VERSION "HIPBNYYYYYYYYYYYYYYYYYYYYYYYYYYYNNNNNNNNNN/4/%%%/4/'%**4NNN///"

NS_ :

BS_ :

BU_ :

BO_ 2632711934 TPDT: 8 Vector__XXX
 SG_ nrSeq  : 0|8@1+ (1,0) [1|255] "" Vector__XXX
 SG_ dataPktizdByt  : 8|56@1+ (1,0) [1|1.15292150460684E+18] "" Vector__XXX

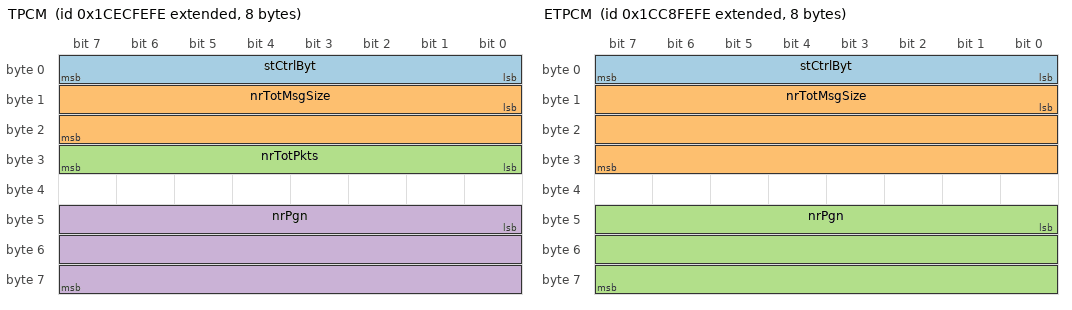
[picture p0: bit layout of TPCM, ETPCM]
BO_ 2632777470 TPCM: 8 Vector__XXX
 SG_ stCtrlByt  : 0|8@1+ (1,0) [0|255] "" Vector__XXX
 SG_ nrTotMsgSize  : 8|16@1+ (1,0) [9|1785] "" Vector__XXX
 SG_ nrTotPkts  : 24|8@1+ (1,0) [2|255] "" Vector__XXX
 SG_ nrPgn  : 40|24@1+ (1,0) [0|16777200] "" Vector__XXX

BO_ 2566839038 SOFT: 8 Vector__XXX
 SG_ nrSwIdnFields  : 0|8@1+ (1,0) [0|250] "steps" Vector__XXX
 SG_ dataSwIdn  : 8|8@1+ (1,0) [0|255] "per byte" Vector__XXX

BO_ 2565537534 RQST: 3 Vector__XXX
 SG_ nrPgn  : 0|24@1+ (1,0) [0|16777215] "" Vector__XXX

BO_ 2565868035 RngChkPrm: 32 Vector__XXX
 SG_ stErrDetnRngChkPrm0  : 0|32@1+ (1,0) [0|4294967295] "" Vector__XXX
 SG_ stErrDetnRngChkPrm1  : 32|32@1+ (1,0) [0|4294967295] "" Vector__XXX
 SG_ stErrDetnRngChkPrm2  : 64|32@1+ (1,0) [0|4294967295] "" Vector__XXX
 SG_ stErrDetnRngChkPrm3  : 96|32@1+ (1,0) [0|4294967295] "" Vector__XXX
 SG_ stErrDetnRngChkPrm4  : 128|32@1+ (1,0) [0|4294967295] "" Vector__XXX
 SG_ stErrDetnRngChkPrm5  : 160|32@1+ (1,0) [0|4294967295] "" Vector__XXX
 SG_ stErrDetnRngChkPrm6  : 192|32@1+ (1,0) [0|4294967295] "" Vector__XXX
 SG_ stErrDetnRngChkPrm7  : 224|32@1+ (1,0) [0|4294967295] "" Vector__XXX

BO_ 2565868291 RngChkInp: 32 Vector__XXX
 SG_ stErrDetnRngChkInpSig0  : 0|32@1+ (1,0) [0|4294967295] "" Vector__XXX
 SG_ stErrDetnRngChkInpSig1  : 32|32@1+ (1,0) [0|4294967295] "" Vector__XXX
 SG_ stErrDetnRngChkInpSig2  : 64|32@1+ (1,0) [0|4294967295] "" Vector__XXX
 SG_ stErrDetnRngChkInpSig3  : 96|32@1+ (1,0) [0|4294967295] "" Vector__XXX
 SG_ stErrDetnRngChkInpSig4  : 128|32@1+ (1,0) [0|4294967295] "" Vector__XXX
 SG_ stErrDetnRngChkInpSig5  : 160|32@1+ (1,0) [0|4294967295] "" Vector__XXX
 SG_ stErrDetnRngChkInpSig6  : 192|32@1+ (1,0) [0|4294967295] "" Vector__XXX
 SG_ stErrDetnRngChkInpSig7  : 224|32@1+ (1,0) [0|4294967295] "" Vector__XXX

BO_ 2559835902 NM: 8 Vector__XXX
 SG_ stChecksErrCod  : 0|8@1+ (1,0) [0|5] "" Vector__XXX
 SG_ flgMnfcCodQlfr  : 8|1@1+ (1,0) [0|1] "" Vector__XXX
 SG_ flgEcuInstQlfr  : 9|1@1+ (1,0) [0|1] "" Vector__XXX
 SG_ flgFctInstQlfr  : 10|1@1+ (1,0) [0|1] "" Vector__XXX
 SG_ flgFctQlfr  : 11|1@1+ (1,0) [0|1] "" Vector__XXX
 SG_ flgVehSysQlfr  : 12|1@1+ (1,0) [0|1] "" Vector__XXX
 SG_ flgVehSysInstQlfr  : 13|1@1+ (1,0) [0|1] "" Vector__XXX
 SG_ flgIndtryGroupQlfr  : 14|1@1+ (1,0) [0|1] "" Vector__XXX
 SG_ flgArbitraryAdrCapableQlfr  : 15|1@1+ (1,0) [0|1] "" Vector__XXX
 SG_ stNameMngtCtrlModIndcr  : 16|4@1+ (1,0) [0|15] "" Vector__XXX
 SG_ dataCmddMnfcCod  : 21|11@1+ (1,0) [0|2047] "" Vector__XXX
 SG_ dataCmddEcuInst  : 32|3@1+ (1,0) [0|7] "" Vector__XXX
 SG_ dataCmddFctInst  : 35|5@1+ (1,0) [0|31] "" Vector__XXX
 SG_ dataCmddFct  : 40|8@1+ (1,0) [0|255] "" Vector__XXX
 SG_ dataCmddVehSys  : 49|7@1+ (1,0) [0|127] "" Vector__XXX
 SG_ dataCmddVehSysInst  : 56|4@1+ (1,0) [0|15] "" Vector__XXX
 SG_ dataCmddIndtryGroup  : 60|3@1+ (1,0) [0|7] "" Vector__XXX
 SG_ flgCmddArbitraryAdrCapable  : 63|1@1+ (1,0) [0|1] "" Vector__XXX

BO_ 2630352638 ETPDT: 8 Vector__XXX
 SG_ nrSeq  : 0|8@1+ (1,0) [1|255] "" Vector__XXX
 SG_ dataPktizdByt  : 8|56@1+ (1,0) [1|1.15292150460684E+18] "" Vector__XXX

BO_ 2630418174 ETPCM: 8 Vector__XXX
 SG_ stCtrlByt  : 0|8@1+ (1,0) [0|255] "" Vector__XXX
 SG_ nrTotMsgSize  : 8|24@1+ (1,0) [1786|117440505] "" Vector__XXX
 SG_ nrPgn  : 40|24@1+ (1,0) [0|16777200] "" Vector__XXX

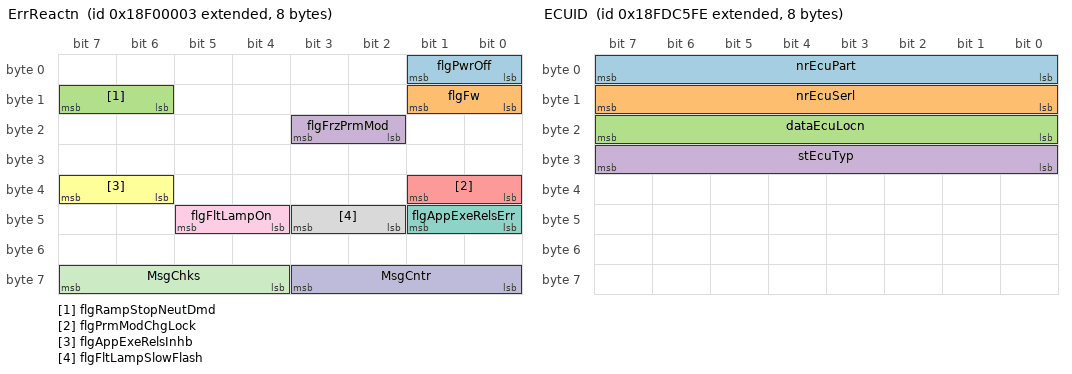
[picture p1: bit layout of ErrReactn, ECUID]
BO_ 2565865475 ErrReactn: 8 Vector__XXX
 SG_ flgPwrOff  : 0|2@1+ (1,0) [0|1] "" Vector__XXX
 SG_ flgFw  : 8|2@1+ (1,0) [0|1] "" Vector__XXX
 SG_ flgRampStopNeutDmd  : 14|2@1+ (1,0) [0|1] "" Vector__XXX
 SG_ flgFrzPrmMod  : 18|2@1+ (1,0) [0|1] "" Vector__XXX
 SG_ flgPrmModChgLock  : 32|2@1+ (1,0) [0|1] "" Vector__XXX
 SG_ flgAppExeRelsInhb  : 38|2@1+ (1,0) [0|1] "" Vector__XXX
 SG_ flgAppExeRelsErr  : 40|2@1+ (1,0) [0|1] "" Vector__XXX
 SG_ flgFltLampSlowFlash  : 42|2@1+ (1,0) [0|1] "" Vector__XXX
 SG_ flgFltLampOn  : 44|2@1+ (1,0) [0|1] "" Vector__XXX
 SG_ MsgCntr  : 56|4@1+ (1,0) [0|15] "" Vector__XXX
 SG_ MsgChks  : 60|4@1+ (1,0) [0|15] "" Vector__XXX

BO_ 2566768126 ECUID: 8 Vector__XXX
 SG_ nrEcuPart  : 0|8@1+ (1,0) [0|255] "per byte" Vector__XXX
 SG_ nrEcuSerl  : 8|8@1+ (1,0) [0|255] "per byte" Vector__XXX
 SG_ dataEcuLocn  : 16|8@1+ (1,0) [0|255] "per byte" Vector__XXX
 SG_ stEcuTyp  : 24|8@1+ (1,0) [0|255] "per byte" Vector__XXX

BO_ 2566835198 DM2: 22 Vector__XXX
 SG_ stProtLamp  : 0|2@1+ (1,0) [0|3] "" Vector__XXX
 SG_ stAmberWarnLamp  : 2|2@1+ (1,0) [0|3] "" Vector__XXX
 SG_ stRedStopLamp  : 4|2@1+ (1,0) [0|3] "" Vector__XXX
 SG_ stMalfctIndcrLamp  : 6|2@1+ (1,0) [0|3] "" Vector__XXX
 SG_ stFlashProtLamp  : 8|2@1+ (1,0) [0|3] "" Vector__XXX
 SG_ stFlashAmberWarnLamp  : 10|2@1+ (1,0) [0|3] "" Vector__XXX
 SG_ stFlashRedStopLamp  : 12|2@1+ (1,0) [0|3] "" Vector__XXX
 SG_ stFlashMalfcIndcrLamp  : 14|2@1+ (1,0) [0|3] "" Vector__XXX
 SG_ DTC1  : 16|32@1+ (1,0) [0|4294967295] "" Vector__XXX
 SG_ DTC2  : 48|32@1+ (1,0) [0|4294967295] "" Vector__XXX
 SG_ DTC3  : 80|32@1+ (1,0) [0|4294967295] "" Vector__XXX
 SG_ DTC4  : 112|32@1+ (1,0) [0|4294967295] "" Vector__XXX
 SG_ DTC5  : 144|32@1+ (1,0) [0|4294967295] "" Vector__XXX

BO_ 2564816638 DM13: 8 Vector__XXX
 SG_ stStopStrtCurDataLnk  : 6|2@1+ (1,0) [0|3] "" Vector__XXX
 SG_ stHldSig  : 28|4@1+ (1,0) [0|15] "" Vector__XXX

BO_ 2566834942 DM1: 22 Vector__XXX
 SG_ stProtLamp  : 0|2@1+ (1,0) [0|3] "" Vector__XXX
 SG_ stAmberWarnLamp  : 2|2@1+ (1,0) [0|3] "" Vector__XXX
 SG_ stRedStopLamp  : 4|2@1+ (1,0) [0|3] "" Vector__XXX
 SG_ stMalfctIndcrLamp  : 6|2@1+ (1,0) [0|3] "" Vector__XXX
 SG_ stFlashProtLamp  : 8|2@1+ (1,0) [0|3] "" Vector__XXX
 SG_ stFlashAmberWarnLamp  : 10|2@1+ (1,0) [0|3] "" Vector__XXX
 SG_ stFlashRedStopLamp  : 12|2@1+ (1,0) [0|3] "" Vector__XXX
 SG_ stFlashMalfcIndcrLamp  : 14|2@1+ (1,0) [0|3] "" Vector__XXX
 SG_ DTC1  : 16|32@1+ (1,0) [0|4294967295] "" Vector__XXX
 SG_ DTC2  : 48|32@1+ (1,0) [0|4294967295] "" Vector__XXX
 SG_ DTC3  : 80|32@1+ (1,0) [0|4294967295] "" Vector__XXX
 SG_ DTC4  : 112|32@1+ (1,0) [0|4294967295] "" Vector__XXX
 SG_ DTC5  : 144|32@1+ (1,0) [0|4294967295] "" Vector__XXX

BO_ 2566838526 CA: 9 Vector__XXX
 SG_ nrIdentity  : 0|21@1+ (1,0) [0|2097151] "" Vector__XXX
 SG_ dataMnfcCode  : 21|11@1+ (1,0) [0|2047] "" Vector__XXX
 SG_ dataEcuInst  : 32|3@1+ (1,0) [0|7] "" Vector__XXX
 SG_ dataFctInst  : 35|5@1+ (1,0) [0|31] "" Vector__XXX
 SG_ dataFct  : 40|8@1+ (1,0) [0|255] "" Vector__XXX
 SG_ dataVehSys  : 49|7@1+ (1,0) [0|127] "" Vector__XXX
 SG_ dataVehSysInst  : 56|4@1+ (1,0) [0|15] "" Vector__XXX
 SG_ dataIndtryGroup  : 60|3@1+ (1,0) [0|7] "" Vector__XXX
 SG_ flgArbitraryAdrCapable  : 63|1@1+ (1,0) [0|1] "" Vector__XXX
 SG_ adrSrcNew  : 64|8@1+ (1,0) [0|253] "" Vector__XXX

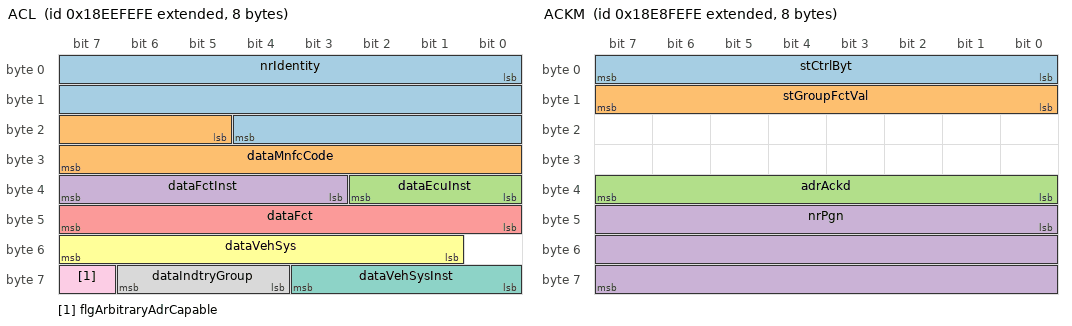
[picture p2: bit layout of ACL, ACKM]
BO_ 2565799678 ACL: 8 Vector__XXX
 SG_ nrIdentity  : 0|21@1+ (1,0) [0|2097151] "" Vector__XXX
 SG_ dataMnfcCode  : 21|11@1+ (1,0) [0|2047] "" Vector__XXX
 SG_ dataEcuInst  : 32|3@1+ (1,0) [0|7] "" Vector__XXX
 SG_ dataFctInst  : 35|5@1+ (1,0) [0|31] "" Vector__XXX
 SG_ dataFct  : 40|8@1+ (1,0) [0|255] "" Vector__XXX
 SG_ dataVehSys  : 49|7@1+ (1,0) [0|127] "" Vector__XXX
 SG_ dataVehSysInst  : 56|4@1+ (1,0) [0|15] "" Vector__XXX
 SG_ dataIndtryGroup  : 60|3@1+ (1,0) [0|7] "" Vector__XXX
 SG_ flgArbitraryAdrCapable  : 63|1@1+ (1,0) [0|1] "" Vector__XXX

BO_ 2565406462 ACKM: 8 Vector__XXX
 SG_ stCtrlByt  : 0|8@1+ (1,0) [0|3] "" Vector__XXX
 SG_ stGroupFctVal  : 8|8@1+ (1,0) [0|250] "" Vector__XXX
 SG_ adrAckd  : 32|8@1+ (1,0) [0|255] "" Vector__XXX
 SG_ nrPgn  : 40|24@1+ (1,0) [0|16777200] "" Vector__XXX

CM_ SG_ 2632711934 dataPktizdByt "Packetized Data (7 bytes).";

CM_ SG_ 2632777470 stCtrlByt "Control Byte specifiying kind of connection management message. See SAE J1939-21.";
CM_ SG_ 2632777470 nrTotMsgSize "Number of bytes to be transmitted. See SAE J1939-21.";
CM_ SG_ 2632777470 nrTotPkts "Total Number of Packets. See SAE J1939-21.";
CM_ SG_ 2632777470 nrPgn "Parameter Group Number of the packeted message. See SAE J1939-21.";

CM_ SG_ 2566839038 nrSwIdnFields "Number of software identification designators represented in the software identification parameter group";
CM_ SG_ 2566839038 dataSwIdn "Software identification of an electronic module. As an example, this parameter may be represented with ASCII characters MMDDYYaa where MM is the month, DD is the day, YY is the year, and aa is the revision number.";

CM_ SG_ 2565537534 nrPgn "Parameter Group Number of the packeted message. See SAE J1939-21.";

CM_ SG_ 2565868035 stErrDetnRngChkPrm0 "Parameter range check bits of all used functions components (Array 0)";
CM_ SG_ 2565868035 stErrDetnRngChkPrm1 "Parameter range check bits of all used functions components (Array 1)";
CM_ SG_ 2565868035 stErrDetnRngChkPrm2 "Parameter range check bits of all used functions components (Array 2)";
CM_ SG_ 2565868035 stErrDetnRngChkPrm3 "Parameter range check bits of all used functions components (Array 3)";
CM_ SG_ 2565868035 stErrDetnRngChkPrm4 "Parameter range check bits of all used functions components (Array 4)";
CM_ SG_ 2565868035 stErrDetnRngChkPrm5 "Parameter range check bits of all used functions components (Array 5)";
CM_ SG_ 2565868035 stErrDetnRngChkPrm6 "Parameter range check bits of all used functions components (Array 6)";
CM_ SG_ 2565868035 stErrDetnRngChkPrm7 "Parameter range check bits of all used functions components (Array 7)";

CM_ SG_ 2565868291 stErrDetnRngChkInpSig0 "Input range check bits of all used functions components (Array 0)";
CM_ SG_ 2565868291 stErrDetnRngChkInpSig1 "Input range check bits of all used functions components (Array 1)";
CM_ SG_ 2565868291 stErrDetnRngChkInpSig2 "Input range check bits of all used functions components (Array 2)";
CM_ SG_ 2565868291 stErrDetnRngChkInpSig3 "Input range check bits of all used functions components (Array 3)";
CM_ SG_ 2565868291 stErrDetnRngChkInpSig4 "Input range check bits of all used functions components (Array 4)";
CM_ SG_ 2565868291 stErrDetnRngChkInpSig5 "Input range check bits of all used functions components (Array 5)";
CM_ SG_ 2565868291 stErrDetnRngChkInpSig6 "Input range check bits of all used functions components (Array 6)";
CM_ SG_ 2565868291 stErrDetnRngChkInpSig7 "Input range check bits of all used functions components (Array 7)";

CM_ SG_ 2559835902 stChecksErrCod "NAME Checksum or error code depending on mode, see SAE J1939-81 chapter 4.6.2.2.1.";
CM_ SG_ 2559835902 flgMnfcCodQlfr "Manufacturer Code qualifier flag, see SAE J1939-81 chapter 4.6.2.2.2.";
CM_ SG_ 2559835902 flgEcuInstQlfr "ECU Instance qualifier flag, see SAE J1939-81 chapter 4.6.2.2.3.";
CM_ SG_ 2559835902 flgFctInstQlfr "Function Instance qualifier flag, see SAE J1939-81 chapter 4.6.2.2.4.";
CM_ SG_ 2559835902 flgFctQlfr "Function qualifier flag, see SAE J1939-81 chapter 4.6.2.2.5.";
CM_ SG_ 2559835902 flgVehSysQlfr "Vehicle system qualifier flag, see SAE J1939-81 chapter 4.6.2.2.6.";
CM_ SG_ 2559835902 flgVehSysInstQlfr "Vehicle system Instance qualifier flag, see SAE J1939-81 chapter 4.6.2.2.7.";
CM_ SG_ 2559835902 flgIndtryGroupQlfr "Industry group qualifier flag, see SAE J1939-81 chapter 4.6.2.2.8.";
CM_ SG_ 2559835902 flgArbitraryAdrCapableQlfr "Arbitrary Address Capable qualifier flag, see SAE J1939-81 chapter 4.6.2.2.9.";
CM_ SG_ 2559835902 stNameMngtCtrlModIndcr "This four bit parameter is used to define the purpose of the NM message. See SAE J1939-81 chapter 4.6.2.2.10.";
CM_ SG_ 2559835902 dataCmddMnfcCod "See SAE J1939-81 chapter 4.6.2.2.11.";
CM_ SG_ 2559835902 dataCmddEcuInst "See SAE J1939-81 chapter 4.6.2.2.12.";
CM_ SG_ 2559835902 dataCmddFctInst "See SAE J1939-81 chapter 4.6.2.2.13.";
CM_ SG_ 2559835902 dataCmddFct "See SAE J1939-81 chapter 4.6.2.2.14.";
CM_ SG_ 2559835902 dataCmddVehSys "See SAE J1939-81 chapter 4.6.2.2.15.";
CM_ SG_ 2559835902 dataCmddVehSysInst "See SAE J1939-81 chapter 4.6.2.2.16.";
CM_ SG_ 2559835902 dataCmddIndtryGroup "See SAE J1939-81 chapter 4.6.2.2.17.";
CM_ SG_ 2559835902 flgCmddArbitraryAdrCapable "See SAE J1939-81 chapter 4.6.2.2.18.";

CM_ SG_ 2630352638 dataPktizdByt "Packetized Data (7 bytes).";

CM_ SG_ 2630418174 stCtrlByt "Control Byte specifiying kind of connection management message. See SAE J1939-21.";
CM_ SG_ 2630418174 nrTotMsgSize "Number of bytes to be transmitted. See SAE J1939-21.";
CM_ SG_ 2630418174 nrPgn "Parameter Group Number of the packeted message. See SAE J1939-21.";

CM_ SG_ 2565865475 flgPwrOff "Error reaction - Emergency power off";
CM_ SG_ 2565865475 flgFw "Error reaction - Free wheeling";
CM_ SG_ 2565865475 flgRampStopNeutDmd "Error reaction - Ramp stop via neutral drive demand";
CM_ SG_ 2565865475 flgFrzPrmMod "Error reaction - Freeze drive mode";
CM_ SG_ 2565865475 flgPrmModChgLock "Error reaction - Drive mode change lock";
CM_ SG_ 2565865475 flgAppExeRelsInhb "Error reaction - Start lock that prevents vehicle movement during power on";
CM_ SG_ 2565865475 flgAppExeRelsErr "Error reaction - Inhibit first appl power on condition";
CM_ SG_ 2565865475 flgFltLampSlowFlash "Error reaction - No reaction executed, Fault Lamp slow flashing";
CM_ SG_ 2565865475 flgFltLampOn "Error reaction - No reaction executed, Fault Lamp on";
CM_ SG_ 2565865475 MsgCntr "The message counter is used to detect situations where the transmitting ECU repeats the same frame all the time. The receiver may use the counter parameter to detect this situation. The transmitting device will increase the message counter in every cycle.";
CM_ SG_ 2565865475 MsgChks "The message checksum is used to verify the signal path from the transmitting device to the receiving device.";

CM_ SG_ 2566768126 nrEcuPart "The part number of the physical ECU.";
CM_ SG_ 2566768126 nrEcuSerl "The serial number of the physical ECU.";
CM_ SG_ 2566768126 dataEcuLocn "The location of the ECU within a network.";
CM_ SG_ 2566768126 stEcuTyp "The type of ECU. One example of a use of the ECU type could be for classifying ECU capabilities, such as I/O.";

CM_ SG_ 2566835198 stProtLamp "This lamp is used to relay trouble code information that is reporting a problem with a vehicle system that is most probably not electronic subsystem related";
CM_ SG_ 2566835198 stAmberWarnLamp "This lamp is used to relay trouble code information that is reporting a problem with the vehicle system but the vehicle need not be immediately stopped";
CM_ SG_ 2566835198 stRedStopLamp "This lamp is used to relay trouble code information that is of a severe enought condition that it warrants stopping the vehicle";
CM_ SG_ 2566835198 stMalfctIndcrLamp "A lamp used to relay only emissions-related trouble code information";
CM_ SG_ 2566835198 stFlashProtLamp "This parameter provides the capability to flash the engine protect lamp (SPN 3041)";
CM_ SG_ 2566835198 stFlashAmberWarnLamp "This parameter provides the capability to flash the AWL (SPN 3040)";
CM_ SG_ 2566835198 stFlashRedStopLamp "This parameter provides the capability to flash the RSL (SPN 3039)";
CM_ SG_ 2566835198 stFlashMalfcIndcrLamp "This parameter provides the capability to flash the MIL (SPN 3038)";
CM_ SG_ 2566835198 DTC1 "Diagnostic Trouble Code";
CM_ SG_ 2566835198 DTC2 "Diagnostic Trouble Code";
CM_ SG_ 2566835198 DTC3 "Diagnostic Trouble Code";
CM_ SG_ 2566835198 DTC4 "Diagnostic Trouble Code";
CM_ SG_ 2566835198 DTC5 "Diagnostic Trouble Code";

CM_ SG_ 2564816638 stStopStrtCurDataLnk "Identifies the action to be performed on the communications port that this parameter was received on:01b = Stop Broadcast,10b = Start Broadcast";
CM_ SG_ 2564816638 stHldSig "Indicator to all nodes that the communication ports that have been acted upon by the “Stop Start Broadcast” PGN are remaining in the modified state.0000b = All Devices,0001b = Devices whose broadcast state has been modified";

CM_ SG_ 2566834942 stProtLamp "This lamp is used to relay trouble code information that is reporting a problem with a vehicle system that is most probably not electronic subsystem related";
CM_ SG_ 2566834942 stAmberWarnLamp "This lamp is used to relay trouble code information that is reporting a problem with the vehicle system but the vehicle need not be immediately stopped";
CM_ SG_ 2566834942 stRedStopLamp "This lamp is used to relay trouble code information that is of a severe enought condition that it warrants stopping the vehicle";
CM_ SG_ 2566834942 stMalfctIndcrLamp "A lamp used to relay only emissions-related trouble code information";
CM_ SG_ 2566834942 stFlashProtLamp "This parameter provides the capability to flash the engine protect lamp (SPN 3041)";
CM_ SG_ 2566834942 stFlashAmberWarnLamp "This parameter provides the capability to flash the AWL (SPN 3040)";
CM_ SG_ 2566834942 stFlashRedStopLamp "This parameter provides the capability to flash the RSL (SPN 3039)";
CM_ SG_ 2566834942 stFlashMalfcIndcrLamp "This parameter provides the capability to flash the MIL (SPN 3038)";
CM_ SG_ 2566834942 DTC1 "Diagnostic Trouble Code";
CM_ SG_ 2566834942 DTC2 "Diagnostic Trouble Code";
CM_ SG_ 2566834942 DTC3 "Diagnostic Trouble Code";
CM_ SG_ 2566834942 DTC4 "Diagnostic Trouble Code";
CM_ SG_ 2566834942 DTC5 "Diagnostic Trouble Code";

CM_ SG_ 2566838526 nrIdentity "Part of the NAME of Commanded Address Target";
CM_ SG_ 2566838526 dataMnfcCode "Part of the NAME of Commanded Address Target";
CM_ SG_ 2566838526 dataEcuInst "Part of the NAME of Commanded Address Target";
CM_ SG_ 2566838526 dataFctInst "Part of the NAME of Commanded Address Target";
CM_ SG_ 2566838526 dataFct "Part of the NAME of Commanded Address Target";
CM_ SG_ 2566838526 dataVehSys "Part of the NAME of Commanded Address Target";
CM_ SG_ 2566838526 dataVehSysInst "Part of the NAME of Commanded Address Target";
CM_ SG_ 2566838526 dataIndtryGroup "Part of the NAME of Commanded Address Target";
CM_ SG_ 2566838526 flgArbitraryAdrCapable "Part of the NAME of Commanded Address Target";
CM_ SG_ 2566838526 adrSrcNew "It contains the source address that is to be assigned to the CA matching the NAME conveyed in the first eight bytes of this Commanded Address message.";

CM_ SG_ 2565799678 nrIdentity "Part of the 8-byte Value which uniquely identifies the particular CA that is claiming the associated address.";
CM_ SG_ 2565799678 dataMnfcCode "Part of the 8-byte Value which uniquely identifies the particular CA that is claiming the associated address.";
CM_ SG_ 2565799678 dataEcuInst "Part of the 8-byte Value which uniquely identifies the particular CA that is claiming the associated address.";
CM_ SG_ 2565799678 dataFctInst "Part of the 8-byte Value which uniquely identifies the particular CA that is claiming the associated address.";
CM_ SG_ 2565799678 dataFct "Part of the 8-byte Value which uniquely identifies the particular CA that is claiming the associated address.";
CM_ SG_ 2565799678 dataVehSys "Part of the 8-byte Value which uniquely identifies the particular CA that is claiming the associated address.";
CM_ SG_ 2565799678 dataVehSysInst "Part of the 8-byte Value which uniquely identifies the particular CA that is claiming the associated address.";
CM_ SG_ 2565799678 dataIndtryGroup "Part of the 8-byte Value which uniquely identifies the particular CA that is claiming the associated address.";
CM_ SG_ 2565799678 flgArbitraryAdrCapable "Part of the 8-byte Value which uniquely identifies the particular CA that is claiming the associated address.";

CM_ SG_ 2565406462 stCtrlByt "Control byte = 0, Positive Acknowledgment (ACK);Control byte = 1, Negative Acknowledgment (NACK);Control byte = 2, Access Denied;Control byte = 3, Cannot Respond;See SAE J1939-21 chapter 5.4.4";
CM_ SG_ 2565406462 stGroupFctVal "Group Function Value, see SAE J1939-21 chapter 5.4.4.";
CM_ SG_ 2565406462 adrAckd "Address of acknowledgment depending on Control Byte.";
CM_ SG_ 2565406462 nrPgn "Parameter Group Number of the acknowledged message (depending on ControlByte). See SAE J1939-21.";

BA_DEF_ SG_  "SigType" ENUM  "Default","Range","RangeSigned","ASCII","Discrete","Control","ReferencePGN","DTC","StringDelimiter","StringLength","StringLengthControl";
BA_DEF_ SG_  "SPN" INT 0 524287;
BA_DEF_ BO_  "GenMsgRequestable" INT 0 1;
BA_DEF_ BO_  "GenMsgSendType" ENUM  "cyclic","NotUsed","NotUsed","NotUsed","NotUsed","NotUsed","NotUsed","IfActive","noMsgSendType";
BA_DEF_ BO_  "VFrameFormat" ENUM  "StandardCAN","ExtendedCAN","reserved","J1939PG";
BA_DEF_ BO_  "GenMsgCycleTime" INT 0 3600000;
BA_DEF_ BO_  "MsgCntrChksSuprtd" INT 0 3;
BA_DEF_ BU_  "NmStationAddress" INT 0 255;
BA_DEF_  "BusType" STRING ;
BA_DEF_  "ProtocolType" STRING ;
BA_DEF_DEF_  "SigType" "Default";
BA_DEF_DEF_  "SPN" 0;
BA_DEF_DEF_  "GenMsgRequestable" 1;
BA_DEF_DEF_  "GenMsgSendType" "noMsgSendType";
BA_DEF_DEF_  "VFrameFormat" "StandardCAN";
BA_DEF_DEF_  "GenMsgCycleTime" 0;
BA_DEF_DEF_  "MsgCntrChksSuprtd" 0;
BA_DEF_DEF_  "NmStationAddress" 254;
BA_DEF_DEF_  "BusType" "";
BA_DEF_DEF_  "ProtocolType" "";
BA_ "ProtocolType" "J1939";
BA_  "BusType" "CAN";

BA_ "GenMsgSendType" BO_ 2632711934 7;
BA_ "VFrameFormat" BO_ 2632711934 3;
BA_ "GenMsgSendType" BO_ 2632777470 7;
BA_ "VFrameFormat" BO_ 2632777470 3;
BA_ "VFrameFormat" BO_ 2566839038 3;
BA_ "GenMsgSendType" BO_ 2565537534 7;
BA_ "VFrameFormat" BO_ 2565537534 3;
BA_ "VFrameFormat" BO_ 2565868035 3;
BA_ "VFrameFormat" BO_ 2565868291 3;
BA_ "GenMsgSendType" BO_ 2559835902 7;
BA_ "VFrameFormat" BO_ 2559835902 3;
BA_ "GenMsgSendType" BO_ 2630352638 7;
BA_ "VFrameFormat" BO_ 2630352638 3;
BA_ "GenMsgSendType" BO_ 2630418174 7;
BA_ "VFrameFormat" BO_ 2630418174 3;
BA_ "GenMsgSendType" BO_ 2565865475 7;
BA_ "VFrameFormat" BO_ 2565865475 3;
BA_ "VFrameFormat" BO_ 2566768126 3;
BA_ "GenMsgSendType" BO_ 2566835198 7;
BA_ "VFrameFormat" BO_ 2566835198 3;
BA_ "GenMsgSendType" BO_ 2564816638 7;
BA_ "VFrameFormat" BO_ 2564816638 3;
BA_ "GenMsgSendType" BO_ 2566834942 7;
BA_ "VFrameFormat" BO_ 2566834942 3;
BA_ "GenMsgSendType" BO_ 2566838526 7;
BA_ "VFrameFormat" BO_ 2566838526 3;
BA_ "GenMsgSendType" BO_ 2565799678 7;
BA_ "VFrameFormat" BO_ 2565799678 3;
BA_ "VFrameFormat" BO_ 2565406462 3;

BA_ "SPN"  SG_ 2632711934 nrSeq 2572;
BA_ "SPN"  SG_ 2632711934 dataPktizdByt 2573;
BA_ "SPN"  SG_ 2632777470 stCtrlByt 2556;
BA_ "SigType"  SG_ 2632777470 stCtrlByt 5;
BA_ "SPN"  SG_ 2632777470 nrTotMsgSize 2557;
BA_ "SPN"  SG_ 2632777470 nrTotPkts 2558;
BA_ "SPN"  SG_ 2632777470 nrPgn 2560;
BA_ "SigType"  SG_ 2632777470 nrPgn 6;
BA_ "SPN"  SG_ 2566839038 nrSwIdnFields 965;
BA_ "SigType"  SG_ 2566839038 nrSwIdnFields 1;
BA_ "SPN"  SG_ 2566839038 dataSwIdn 234;
BA_ "SigType"  SG_ 2566839038 dataSwIdn 8;
BA_ "SPN"  SG_ 2565537534 nrPgn 2560;
BA_ "SigType"  SG_ 2565537534 nrPgn 6;
BA_ "SPN"  SG_ 2559835902 stChecksErrCod 5657;
BA_ "SigType"  SG_ 2559835902 stChecksErrCod 1;
BA_ "SPN"  SG_ 2559835902 flgMnfcCodQlfr 5658;
BA_ "SPN"  SG_ 2559835902 flgEcuInstQlfr 5659;
BA_ "SPN"  SG_ 2559835902 flgFctInstQlfr 5660;
BA_ "SPN"  SG_ 2559835902 flgFctQlfr 5661;
BA_ "SPN"  SG_ 2559835902 flgVehSysQlfr 5662;
BA_ "SPN"  SG_ 2559835902 flgVehSysInstQlfr 5663;
BA_ "SPN"  SG_ 2559835902 flgIndtryGroupQlfr 5664;
BA_ "SPN"  SG_ 2559835902 flgArbitraryAdrCapableQlfr 5665;
BA_ "SPN"  SG_ 2559835902 stNameMngtCtrlModIndcr 5666;
BA_ "SPN"  SG_ 2559835902 dataCmddMnfcCod 5667;
BA_ "SPN"  SG_ 2559835902 dataCmddEcuInst 5668;
BA_ "SPN"  SG_ 2559835902 dataCmddFctInst 5669;
BA_ "SPN"  SG_ 2559835902 dataCmddFct 5670;
BA_ "SPN"  SG_ 2559835902 dataCmddVehSys 5671;
BA_ "SPN"  SG_ 2559835902 dataCmddVehSysInst 5672;
BA_ "SPN"  SG_ 2559835902 dataCmddIndtryGroup 5673;
BA_ "SPN"  SG_ 2559835902 flgCmddArbitraryAdrCapable 5674;
BA_ "SPN"  SG_ 2630352638 nrSeq 2572;
BA_ "SPN"  SG_ 2630352638 dataPktizdByt 2573;
BA_ "SPN"  SG_ 2630418174 stCtrlByt 2556;
BA_ "SigType"  SG_ 2630418174 stCtrlByt 5;
BA_ "SPN"  SG_ 2630418174 nrTotMsgSize 2557;
BA_ "SPN"  SG_ 2630418174 nrPgn 2560;
BA_ "SigType"  SG_ 2630418174 nrPgn 6;
BA_ "SPN"  SG_ 2565865475 MsgCntr 4206;
BA_ "SPN"  SG_ 2565865475 MsgChks 4207;
BA_ "SPN"  SG_ 2566768126 nrEcuPart 2901;
BA_ "SigType"  SG_ 2566768126 nrEcuPart 8;
BA_ "SPN"  SG_ 2566768126 nrEcuSerl 2902;
BA_ "SigType"  SG_ 2566768126 nrEcuSerl 8;
BA_ "SPN"  SG_ 2566768126 dataEcuLocn 2903;
BA_ "SigType"  SG_ 2566768126 dataEcuLocn 8;
BA_ "SPN"  SG_ 2566768126 stEcuTyp 2904;
BA_ "SigType"  SG_ 2566768126 stEcuTyp 8;
BA_ "SPN"  SG_ 2566835198 stProtLamp 987;
BA_ "SigType"  SG_ 2566835198 stProtLamp 4;
BA_ "SPN"  SG_ 2566835198 stAmberWarnLamp 624;
BA_ "SigType"  SG_ 2566835198 stAmberWarnLamp 4;
BA_ "SPN"  SG_ 2566835198 stRedStopLamp 623;
BA_ "SigType"  SG_ 2566835198 stRedStopLamp 4;
BA_ "SPN"  SG_ 2566835198 stMalfctIndcrLamp 1213;
BA_ "SigType"  SG_ 2566835198 stMalfctIndcrLamp 4;
BA_ "SPN"  SG_ 2566835198 stFlashProtLamp 3041;
BA_ "SigType"  SG_ 2566835198 stFlashProtLamp 4;
BA_ "SPN"  SG_ 2566835198 stFlashAmberWarnLamp 3040;
BA_ "SigType"  SG_ 2566835198 stFlashAmberWarnLamp 4;
BA_ "SPN"  SG_ 2566835198 stFlashRedStopLamp 3039;
BA_ "SigType"  SG_ 2566835198 stFlashRedStopLamp 4;
BA_ "SPN"  SG_ 2566835198 stFlashMalfcIndcrLamp 3038;
BA_ "SigType"  SG_ 2566835198 stFlashMalfcIndcrLamp 4;
BA_ "SigType"  SG_ 2566835198 DTC1 7;
BA_ "SigType"  SG_ 2566835198 DTC2 7;
BA_ "SigType"  SG_ 2566835198 DTC3 7;
BA_ "SigType"  SG_ 2566835198 DTC4 7;
BA_ "SigType"  SG_ 2566835198 DTC5 7;
BA_ "SPN"  SG_ 2564816638 stStopStrtCurDataLnk 1230;
BA_ "SigType"  SG_ 2564816638 stStopStrtCurDataLnk 5;
BA_ "SPN"  SG_ 2564816638 stHldSig 1236;
BA_ "SigType"  SG_ 2564816638 stHldSig 5;
BA_ "SPN"  SG_ 2566834942 stProtLamp 987;
BA_ "SigType"  SG_ 2566834942 stProtLamp 4;
BA_ "SPN"  SG_ 2566834942 stAmberWarnLamp 624;
BA_ "SigType"  SG_ 2566834942 stAmberWarnLamp 4;
BA_ "SPN"  SG_ 2566834942 stRedStopLamp 623;
BA_ "SigType"  SG_ 2566834942 stRedStopLamp 4;
BA_ "SPN"  SG_ 2566834942 stMalfctIndcrLamp 1213;
BA_ "SigType"  SG_ 2566834942 stMalfctIndcrLamp 4;
BA_ "SPN"  SG_ 2566834942 stFlashProtLamp 3041;
BA_ "SigType"  SG_ 2566834942 stFlashProtLamp 4;
BA_ "SPN"  SG_ 2566834942 stFlashAmberWarnLamp 3040;
BA_ "SigType"  SG_ 2566834942 stFlashAmberWarnLamp 4;
BA_ "SPN"  SG_ 2566834942 stFlashRedStopLamp 3039;
BA_ "SigType"  SG_ 2566834942 stFlashRedStopLamp 4;
BA_ "SPN"  SG_ 2566834942 stFlashMalfcIndcrLamp 3038;
BA_ "SigType"  SG_ 2566834942 stFlashMalfcIndcrLamp 4;
BA_ "SigType"  SG_ 2566834942 DTC1 7;
BA_ "SigType"  SG_ 2566834942 DTC2 7;
BA_ "SigType"  SG_ 2566834942 DTC3 7;
BA_ "SigType"  SG_ 2566834942 DTC4 7;
BA_ "SigType"  SG_ 2566834942 DTC5 7;
BA_ "SPN"  SG_ 2566838526 nrIdentity 2837;
BA_ "SPN"  SG_ 2566838526 dataMnfcCode 2838;
BA_ "SPN"  SG_ 2566838526 dataEcuInst 2840;
BA_ "SPN"  SG_ 2566838526 dataFctInst 2839;
BA_ "SPN"  SG_ 2566838526 dataFct 2841;
BA_ "SPN"  SG_ 2566838526 dataVehSys 2842;
BA_ "SPN"  SG_ 2566838526 dataVehSysInst 2843;
BA_ "SPN"  SG_ 2566838526 dataIndtryGroup 2846;
BA_ "SPN"  SG_ 2566838526 flgArbitraryAdrCapable 2844;
BA_ "SPN"  SG_ 2566838526 adrSrcNew 2847;
BA_ "SPN"  SG_ 2565799678 nrIdentity 2837;
BA_ "SPN"  SG_ 2565799678 dataMnfcCode 2838;
BA_ "SPN"  SG_ 2565799678 dataEcuInst 2840;
BA_ "SPN"  SG_ 2565799678 dataFctInst 2839;
BA_ "SPN"  SG_ 2565799678 dataFct 2841;
BA_ "SPN"  SG_ 2565799678 dataVehSys 2842;
BA_ "SPN"  SG_ 2565799678 dataVehSysInst 2843;
BA_ "SPN"  SG_ 2565799678 dataIndtryGroup 2846;
BA_ "SPN"  SG_ 2565799678 flgArbitraryAdrCapable 2844;
BA_ "SPN"  SG_ 2565406462 stCtrlByt 2541;
BA_ "SPN"  SG_ 2565406462 stGroupFctVal 2542;
BA_ "SigType"  SG_ 2565406462 stGroupFctVal 1;
BA_ "SPN"  SG_ 2565406462 nrPgn 2543;
BA_ "SigType"  SG_ 2565406462 nrPgn 6;

BA_ "MsgCntrChksSuprtd" BO_ 2565865475 1;

VAL_ 2565865475 flgPwrOff  0 "Off" 1 "On" 2 "Error" 3 "Not available"  ;
VAL_ 2565865475 flgFw  0 "Off" 1 "On" 2 "Error" 3 "Not available"  ;
VAL_ 2565865475 flgRampStopNeutDmd  0 "Off" 1 "On" 2 "Error" 3 "Not available"  ;
VAL_ 2565865475 flgFrzPrmMod  0 "Off" 1 "On" 2 "Error" 3 "Not available"  ;
VAL_ 2565865475 flgPrmModChgLock  0 "Off" 1 "On" 2 "Error" 3 "Not available"  ;
VAL_ 2565865475 flgAppExeRelsInhb  0 "Off" 1 "On" 2 "Error" 3 "Not available"  ;
VAL_ 2565865475 flgAppExeRelsErr  0 "Off" 1 "On" 2 "Error" 3 "Not available"  ;
VAL_ 2565865475 flgFltLampSlowFlash  0 "Off" 1 "On" 2 "Error" 3 "Not available"  ;
VAL_ 2565865475 flgFltLampOn  0 "Off" 1 "On" 2 "Error" 3 "Not available"  ;
VAL_ 2566835198 stProtLamp  0 "Lamp off" 1 "Lamp on" 2 "Reserved" 3 "Not available"  ;
VAL_ 2566835198 stAmberWarnLamp  0 "Lamp off" 1 "Lamp on" 2 "Reserved" 3 "Not available"  ;
VAL_ 2566835198 stRedStopLamp  0 "Lamp off" 1 "Lamp on" 2 "Reserved" 3 "Not available"  ;
VAL_ 2566835198 stMalfctIndcrLamp  0 "Lamp off" 1 "Lamp on" 2 "Reserved" 3 "Not available"  ;
VAL_ 2566835198 stFlashProtLamp  0 "Slow Flash" 1 "Fast Flash" 2 "Reserved" 3 "Unavailable"  ;
VAL_ 2566835198 stFlashAmberWarnLamp  0 "Slow Flash" 1 "Fast Flash" 2 "Reserved" 3 "Unavailable"  ;
VAL_ 2566835198 stFlashRedStopLamp  0 "Slow Flash" 1 "Fast Flash" 2 "Reserved" 3 "Unavailable"  ;
VAL_ 2566835198 stFlashMalfcIndcrLamp  0 "Slow Flash" 1 "Fast Flash" 2 "Reserved" 3 "Unavailable"  ;
VAL_ 2566834942 stProtLamp  0 "Lamp off" 1 "Lamp on" 2 "Reserved" 3 "Not available"  ;
VAL_ 2566834942 stAmberWarnLamp  0 "Lamp off" 1 "Lamp on" 2 "Reserved" 3 "Not available"  ;
VAL_ 2566834942 stRedStopLamp  0 "Lamp off" 1 "Lamp on" 2 "Reserved" 3 "Not available"  ;
VAL_ 2566834942 stMalfctIndcrLamp  0 "Lamp off" 1 "Lamp on" 2 "Reserved" 3 "Not available"  ;
VAL_ 2566834942 stFlashProtLamp  0 "Slow Flash" 1 "Fast Flash" 2 "Reserved" 3 "Unavailable"  ;
VAL_ 2566834942 stFlashAmberWarnLamp  0 "Slow Flash" 1 "Fast Flash" 2 "Reserved" 3 "Unavailable"  ;
VAL_ 2566834942 stFlashRedStopLamp  0 "Slow Flash" 1 "Fast Flash" 2 "Reserved" 3 "Unavailable"  ;
VAL_ 2566834942 stFlashMalfcIndcrLamp  0 "Slow Flash" 1 "Fast Flash" 2 "Reserved" 3 "Unavailable"  ;
